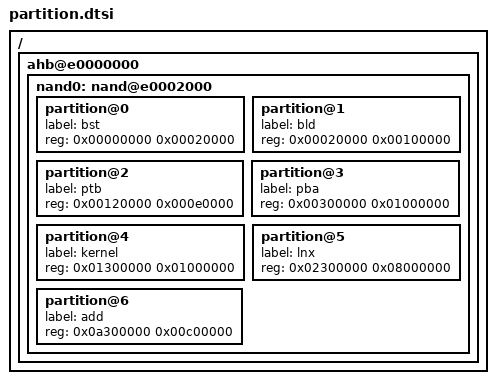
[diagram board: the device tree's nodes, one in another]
/*
 * Copyright (C) 2013 Ambarella,Inc. - http://www.ambarella.com/
 * Author: Cao Rongrong <rrcao@ambarella.com>
 *
 * This program is free software; you can redistribute it and/or modify
 * it under the terms of the GNU General Public License version 2 as
 * published by the Free Software Foundation.
 */

/{
	ahb@e0000000 {
		nand0: nand@e0002000 {
			#address-cells = <1>;
			#size-cells = <1>;

			partition@0 {
				label = "bst";
				reg = <0x00000000 0x00020000>;
			};

			partition@1 {
				label = "bld";
				reg = <0x00020000 0x00100000>;
			};

			partition@2 {
				label = "ptb";
				reg = <0x00120000 0x000e0000>;
			};

			partition@3 {
				label = "pba";
				reg = <0x00300000 0x01000000>;
			};

			partition@4 {
				label = "kernel";
				reg = <0x01300000 0x01000000>;
			};

			partition@5 {
				label = "lnx";
				reg = <0x02300000 0x08000000>;
			};

			partition@6 {
				label = "add";
				reg = <0x0a300000 0x00c00000>;
			};
		};
	};
};
